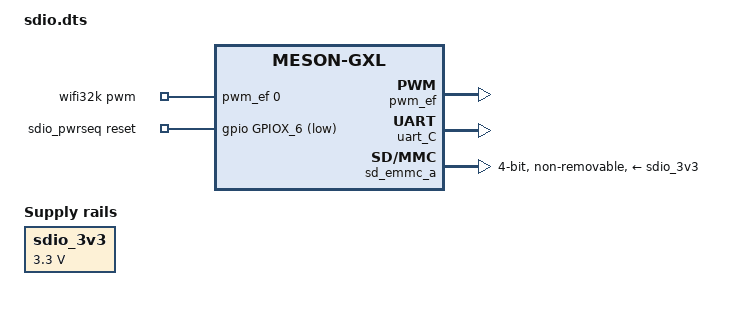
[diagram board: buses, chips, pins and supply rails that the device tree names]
// SPDX-License-Identifier: (GPL-2.0-or-later OR MIT)
/*
 * Copyright (c) 2020 BayLibre, SAS.
 * Author: Nicolas Belin <nbelin@baylibre.com>
 */
/*
 * Summary: SDIO on emmc_a. This includes enabling pwm-e (the WiFi 32k
 * clock) and uart_C (Bluetooth).
 *
 * Pins (Header.Pin  Name  Pad  Ref — cross-ref gpio.map):
 *   7J1.19   GPIOX_8       B4      BTPCM_DOUT
 *   7J1.21   GPIOX_9       B3      BTPCM_DIN
 *   7J1.22   GPIOX_0       A2      WIFI_SD_D0
 *   7J1.23   GPIOX_11      C4      BTPCM_CLK
 *   7J1.24   GPIOX_10      C5      BTPCM_SYNC
 *   7J1.26   GPIOX_1       C3      WIFI_SD_D1
 *   7J1.32   GPIOX_16      A3      WIFI_32K
 *   7J1.33   GPIOX_6       D2      WIFI_PWREN
 *   7J1.36   GPIOX_2       C2      WIFI_SD_D2
 *   7J1.37   GPIOX_5       D3      WIFI_SD_CMD
 *   7J1.38   GPIOX_3       B1      WIFI_SD_D3
 *   7J1.40   GPIOX_4       B2      WIFI_SD_CLK
 *
 * Requires: pwm-e
 *
 * Resource-provides: bus:uart_C
 * Resource-requires: pwm_ef.ch0@7J1-32
 *
 * Notes:
 * Its pwm_ef fragment is pwm-e's, verbatim: the requirement records that the
 * two share 7J1.32 by design, not by collision.
 */
/dts-v1/;
/plugin/;

#include <dt-bindings/gpio/gpio.h>
#include <dt-bindings/gpio/meson-gxl-gpio.h>

/ {
	compatible = "libre-computer,aml-s905x-cc",
		"libretech,aml-s905x-cc",
		"libre-computer,aml-s905x-cc-v2",
		"libretech,aml-s905x-cc-v2",
		"libre-computer,aml-s905x-cc-v3",
		"libretech,aml-s905x-cc-v3",
		"amlogic,s905x",
		"amlogic,meson-gxl";
	fragment@0 {
		target = <&pwm_ef>;

		__overlay__ {
			status = "okay";
			pinctrl-0 = <&pwm_e_pins>;
			pinctrl-names = "default";
		};
	};

	fragment@1 {
		target-path = "/aliases";

		__overlay__ {
			serial1 = "/soc/bus@c1100000/serial@8700";
		};
	};

	fragment@2 {
		target = <&uart_C>;

		__overlay__ {
			status = "okay";
			pinctrl-0 = <&uart_c_pins>, <&uart_c_cts_rts_pins>;
			pinctrl-names = "default";
			uart-has-rtscts;
		};
	};

	fragment@3 {
		target-path = "/";

		__overlay__ {
			wifi32k: wifi32k {
				compatible = "pwm-clock";
				#clock-cells = <0>;
				clock-frequency = <32768>;
				pwms = <&pwm_ef 0 30518 0>; /* PWM_E at 32.768KHz */
			};

			sdio_pwrseq: sdio-pwrseq {
				compatible = "mmc-pwrseq-simple";
				reset-gpios = <&gpio GPIOX_6 GPIO_ACTIVE_LOW>;
				clocks = <&wifi32k>;
				clock-names = "ext_clock";
			};

			/*
			 * The header's 3.3V rail. This dt/ serves Le Potato and,
			 * via symlink, Sweet and Das Potato, whose base DTBs name
			 * that rail differently (vcc_3v3 vs vddio_ao3v3) -- a
			 * reference to either label fails to apply on the other.
			 * Both are always-on fixed 3.3V supplies, so describing it
			 * here changes nothing electrically.
			 */
			sdio_3v3: regulator-sdio-3v3 {
				compatible = "regulator-fixed";
				regulator-name = "SDIO_3V3";
				regulator-min-microvolt = <3300000>;
				regulator-max-microvolt = <3300000>;
				regulator-always-on;
			};
		};
	};

	fragment@4 {
		target = <&sd_emmc_a>;

		__overlay__ {
			status = "okay";
			pinctrl-0 = <&sdio_pins>;
			pinctrl-1 = <&sdio_clk_gate_pins>;
			pinctrl-names = "default", "clk-gate";
			#address-cells = <1>;
			#size-cells = <0>;

			bus-width = <4>;
			cap-sd-highspeed;
			max-frequency = <50000000>;

			non-removable;
			disable-wp;

			mmc-pwrseq = <&sdio_pwrseq>;

			vmmc-supply = <&sdio_3v3>;
			vqmmc-supply = <&sdio_3v3>;
		};
	};
};
